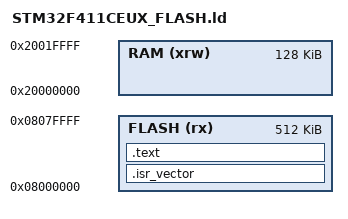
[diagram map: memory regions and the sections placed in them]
/*
******************************************************************************
**
** @file        : LinkerScript.ld
**
** @author      : Auto-generated by STM32CubeIDE
**
** @brief       : Linker script for STM32F411CEUx Device from STM32F4 series
**                      512Kbytes FLASH
**                      128Kbytes RAM
**
**                Set heap size, stack size and stack location according
**                to application requirements.
**
**                Set memory bank area and size if external memory is used
**
**  Target      : STMicroelectronics STM32
**
**  Distribution: The file is distributed as is, without any warranty
**                of any kind.
**
******************************************************************************
** @attention
**
** <h2><center>&copy; Copyright (c) 2021 STMicroelectronics.
** All rights reserved.</center></h2>
**
** This software component is licensed by ST under BSD 3-Clause license,
** the "License"; You may not use this file except in compliance with the
** License. You may obtain a copy of the License at:
**                        opensource.org/licenses/BSD-3-Clause
**
******************************************************************************
*/

/* Entry Point */
ENTRY(reset_handler)

/* Highest address of the user mode stack */
_estack = ORIGIN(RAM) + LENGTH(RAM); /* end of "RAM" Ram type memory */

_Min_Heap_Size = 0x200; /* required amount of heap */
_Min_Stack_Size = 0x400; /* required amount of stack */

/* Memories definition */
MEMORY
{
  RAM    (xrw)    : ORIGIN = 0x20000000,   LENGTH = 128K
  FLASH    (rx)    : ORIGIN = 0x8000000,   LENGTH = 512K
}

/* Sections */
SECTIONS
{
  /* The startup code into "FLASH" Rom type memory */
  .isr_vector :
  {
    . = ALIGN(4);
    KEEP(*(.isr_vector)) /* Startup code */
    . = ALIGN(4);
  } >FLASH

  /* The program code and other data into "FLASH" Rom type memory */
  .text :
  {
    . = ALIGN(4);
    *(.text)           /* .text sections (code) */
    *(.text*)          /* .text* sections (code) */
    . = ALIGN(4);
    _etext = .;        /* define a global symbols at end of code */
  } >FLASH
}
